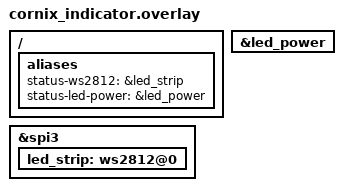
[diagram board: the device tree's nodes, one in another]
&spi3 {
    status = "okay";

    led_strip: ws2812@0 {
        status = "okay";
    };
};

&led_power {
    status = "okay";
};

/ {
    aliases {
        status-ws2812 = &led_strip;
        status-led-power = &led_power;
    };
};
